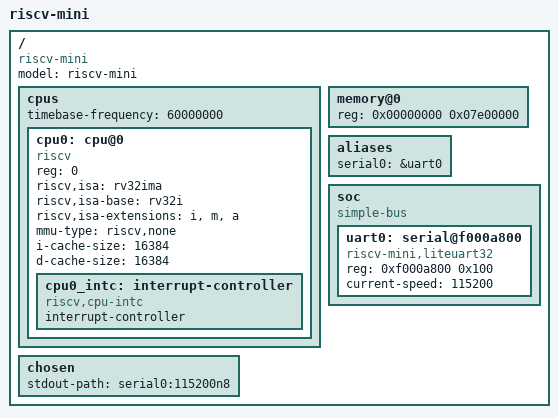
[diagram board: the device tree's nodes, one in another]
// SPDX-License-Identifier: GPL-2.0+
/*
 * Minimal build-time fallback DTB for the riscv-mini board
 * (TangPrimer 20K, VexRiscv RV32IMA, S-mode under OpenSBI FW_PAYLOAD).
 *
 * CONFIG_OF_BOARD=y: at runtime U-Boot uses the DTB handed over by OpenSBI
 * (gd->arch.firmware_fdt_addr, 0x01080000). This file only satisfies the
 * build-time dtbs target.
 */

/dts-v1/;

/ {
	#address-cells = <1>;
	#size-cells = <1>;
	model = "riscv-mini";
	compatible = "riscv-mini";

	cpus: cpus {
		#address-cells = <1>;
		#size-cells = <0>;
		timebase-frequency = <60000000>;

		cpu0: cpu@0 {
			device_type = "cpu";
			compatible = "riscv";
			reg = <0>;
			riscv,isa = "rv32ima";
			riscv,isa-base = "rv32i";
			riscv,isa-extensions = "i", "m", "a";
			mmu-type = "riscv,none";
			i-cache-size = <16384>;
			d-cache-size = <16384>;
			cpu0_intc: interrupt-controller {
				compatible = "riscv,cpu-intc";
				interrupt-controller;
				#interrupt-cells = <1>;
			};
		};
	};

	memory@0 {
		device_type = "memory";
		reg = <0x00000000 0x07e00000>;
	};

	aliases {
		serial0 = &uart0;
	};

	chosen {
		stdout-path = "serial0:115200n8";
	};

	soc: soc {
		#address-cells = <1>;
		#size-cells = <1>;
		compatible = "simple-bus";
		ranges;
		bootph-all;

		uart0: serial@f000a800 {
			compatible = "riscv-mini,liteuart32";
			reg = <0xf000a800 0x100>;
			current-speed = <115200>;
			bootph-all;
		};
	};
};
